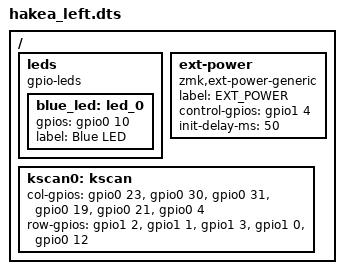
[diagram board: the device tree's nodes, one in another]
/*
 * Copyright (c) 2021 Thys de Wet (vattern)
 *
 * SPDX-License-Identifier: MIT
 */

/dts-v1/;
#include <nordic/nrf52840_qiaa.dtsi>
#include <dt-bindings/zmk/matrix_transform.h>
#include "hakea.dtsi"
/ {

leds {
  compatible = "gpio-leds";
  blue_led: led_0 {
    gpios = <&gpio0 10 GPIO_ACTIVE_HIGH>;
    label = "Blue LED";
  };
};
ext-power {
    compatible = "zmk,ext-power-generic";
    label = "EXT_POWER";
    control-gpios = <&gpio1 4 GPIO_ACTIVE_HIGH>;
    init-delay-ms = <50>;
  };
kscan0: kscan {
    col-gpios
        = <&gpio0 23  GPIO_ACTIVE_HIGH>
        , <&gpio0 30   GPIO_ACTIVE_HIGH>
        , <&gpio0 31   GPIO_ACTIVE_HIGH>
        , <&gpio0 19   GPIO_ACTIVE_HIGH>
        , <&gpio0 21   GPIO_ACTIVE_HIGH>
        , <&gpio0 4  GPIO_ACTIVE_HIGH>
        ;
    row-gpios
        = <&gpio1 2 (GPIO_ACTIVE_HIGH | GPIO_PULL_DOWN)>
        , <&gpio1 1  (GPIO_ACTIVE_HIGH | GPIO_PULL_DOWN)>
        , <&gpio1 3  (GPIO_ACTIVE_HIGH | GPIO_PULL_DOWN)>
        , <&gpio1 0  (GPIO_ACTIVE_HIGH | GPIO_PULL_DOWN)>
        , <&gpio0 12  (GPIO_ACTIVE_HIGH | GPIO_PULL_DOWN)>
        ;
        };
    };
